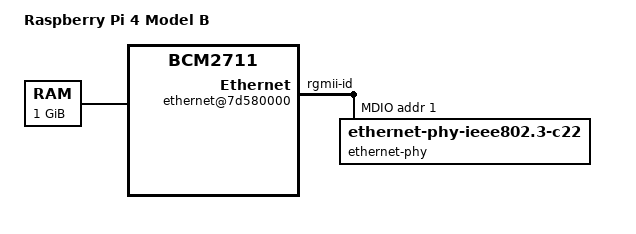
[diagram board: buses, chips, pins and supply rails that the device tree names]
// SPDX-License-Identifier: BSD-3-Clause
// Copyright (c) 2026, Bo Maryniuk and RavenBSD contributors
// Generated by tests/fixtures/pi4-genet/generate.py; fixture pi4-genet-no-mac.
/dts-v1/;

/ {
    compatible = "raspberrypi,4-model-b", "brcm,bcm2711";
    model = "Raspberry Pi 4 Model B";
    #address-cells = <0x2>;
    #size-cells = <0x2>;
    aliases {
        ethernet0 = "/scb/ethernet@7d580000";
    };
    memory@0 {
        device_type = "memory";
        reg = <0x0 0x0 0x0 0x40000000>;
    };
    scb {
        compatible = "simple-bus";
        #address-cells = <0x2>;
        #size-cells = <0x2>;
        ranges = <0x0 0x7c000000 0x0 0xfc000000 0x0 0x3800000 0x6 0x0 0x6 0x0 0x0 0x40000000>;
        dma-ranges = <0x4 0x7c000000 0x0 0xfc000000 0x0 0x3800000 0x0 0x0 0x0 0x0 0x4 0x0>;
        ethernet@7d580000 {
            compatible = "brcm,bcm2711-genet-v5";
            reg = <0x0 0x7d580000 0x0 0x10000>;
            #address-cells = <0x1>;
            #size-cells = <0x1>;
            interrupts = <0x0 0x9d 0x4 0x0 0x9e 0x4>;
            status = "okay";
            phy-mode = "rgmii-id";
            phy-handle = <0x1>;
            mdio@e14 {
                compatible = "brcm,genet-mdio-v5";
                reg = <0xe14 0x8>;
                reg-names = "mdio";
                #address-cells = <0x1>;
                #size-cells = <0x0>;
                ethernet-phy@1 {
                    compatible = "ethernet-phy-ieee802.3-c22";
                    reg = <0x1>;
                    phandle = <0x1>;
                };
            };
        };
    };
};
